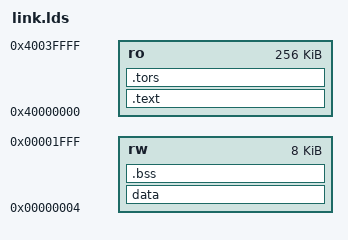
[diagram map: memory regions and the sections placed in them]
OUTPUT_ARCH(mn10300)
ENTRY(_reset_handler)

MEMORY
{
	rw    : o = 0x00000004, l = 0x00001ffc
	ro    : o = 0x40000000, l = 0x00040000
}

SECTIONS
{
	.text :
	{
		 ___text = . ; 
		*(.text)
		*(.strings)
		*(.rodata*)
		*(.glue*)
		 ___text_end = . ; 
	}  > ro
	.tors :
	{
		. = ALIGN(4);
		___ctors = . ;
		*(.ctors)
		___ctors_end = . ;
		___dtors = . ;
		*(.dtors)
		___dtors_end = . ;
	} > ro
	data : AT (ADDR(.tors) + SIZEOF(.tors))
	{
	    ___data_rom = ADDR(.tors) + SIZEOF(.tors);
		___data = . ;
		*(.data)
		___data_end = . ;
	} > rw
	.bss :
	{
		___bss = . ;
		*(.bss)
		*(COMMON)
		___bss_end = . ;  
	} > rw
}

